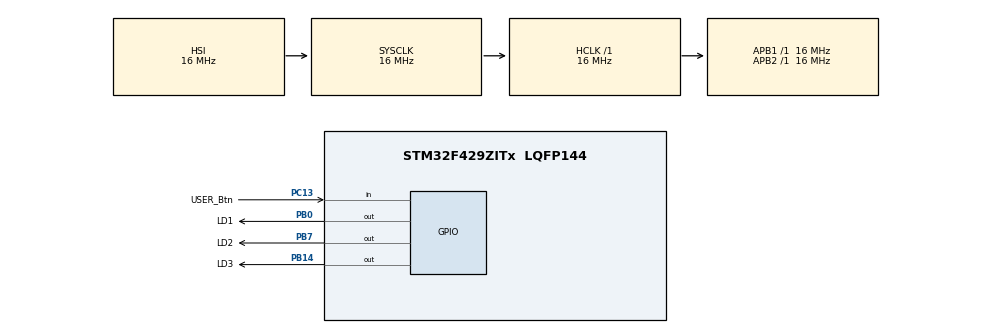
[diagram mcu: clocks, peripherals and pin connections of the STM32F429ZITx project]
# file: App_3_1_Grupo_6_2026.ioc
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Mcu.Family=STM32F4
Mcu.Name=STM32F429ZITx
Mcu.Package=LQFP144
NVIC.PriorityGroup=NVIC_PRIORITYGROUP_4
PB0.GPIO_Label=LD1
PB0.Signal=GPIO_Output
PB14.GPIO_Label=LD3
PB14.Signal=GPIO_Output
PB7.GPIO_Label=LD2
PB7.Signal=GPIO_Output
PC13.GPIO_Label=USER_Btn
PC13.Signal=GPIO_Input
ProjectManager.HeapSize=0x200
ProjectManager.StackSize=0x400
ProjectManager.TargetToolchain=STM32CubeIDE
RCC.AHBFreq_Value=16000000
RCC.APB1Freq_Value=16000000
RCC.APB2Freq_Value=16000000
RCC.CortexFreq_Value=16000000
RCC.HSE_VALUE=25000000
RCC.HSI_VALUE=16000000
RCC.LSE_VALUE=32768
RCC.SYSCLKFreq_VALUE=16000000
RCC.VCOOutputFreq_Value=192000000
board=custom

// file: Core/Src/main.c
/* USER CODE BEGIN Header */
/**
  ******************************************************************************
  * @file           : main.c
  * @brief          : Main program body
  ******************************************************************************
  * @attention
  *
  * Copyright (c) 2026 STMicroelectronics.
  * All rights reserved.
  *
  * This software is licensed under terms that can be found in the LICENSE file
  * in the root directory of this software component.
  * If no LICENSE file comes with this software, it is provided AS-IS.
  *
  ******************************************************************************
  */
/* USER CODE END Header */
#include "main.h"
/*App 1.1: Desarrolle una aplicaci´on que encienda y apague de manera secuencial
los tres leds onboard de la placa de desarrollo. La secuencia debe encender 200 ms y
apagar 200 ms cada led comenzando por el LED1 (Green), continuando con el LED2 (Blue) y
luego el LED3 (Red) para volver a iniciar con el LED1. La aplicaci´on debe ser de car´acter
general, de manera que pueda extenderse a una cantidad mayor de leds con m´ınimas modificaciones,
por este motivo se sugiere que use un vector para el manejo de los Leds.*/
/* USER CODE BEGIN Includes */
#include "API_GPIO.h"
/* USER CODE END Includes */

#define LED1 GPIO_PIN_0    // verde
#define LED2 GPIO_PIN_7    // azul
#define LED3 GPIO_PIN_14   // rojo

void SystemClock_Config(void);
//tatic void MX_GPIO_Init(void);

int main(void)
{

  /* MCU Configuration--------------------------------------------------------*/

  /* Reset of all peripherals, Initializes the Flash interface and the Systick. */
  HAL_Init();

  /* Configure the system clock */
  SystemClock_Config();

  /* Initialize all configured peripherals */
  MX_GPIO_Init();
  /* USER CODE BEGIN 2 */
  /* USER CODE BEGIN 2 */
  led_t leds[] = {LED1, LED2, LED3};   // vector con los leds en el orden de la secuencia
  uint8_t cantLeds = 3;                // cuantos leds hay
  /* USER CODE END 2 */
  /* USER CODE END 2 */

  /* Infinite loop */
  while (1)
  {

    /* USER CODE BEGIN 3 */

	  for (uint8_t i = 0; i < cantLeds; i++)
	  {
		  writeLedOn_GPIO(leds[i]); // acá, leds[i] es el led que toca
		  HAL_Delay(200);
		  writeLedOff_GPIO(leds[i]);
		  HAL_Delay(200);
	  }

  }

  /* USER CODE END 3 */
}

void SystemClock_Config(void)
{
  RCC_OscInitTypeDef RCC_OscInitStruct = {0};
  RCC_ClkInitTypeDef RCC_ClkInitStruct = {0};

  /** Configure the main internal regulator output voltage
  */
  __HAL_RCC_PWR_CLK_ENABLE();
  __HAL_PWR_VOLTAGESCALING_CONFIG(PWR_REGULATOR_VOLTAGE_SCALE3);

  /** Initializes the RCC Oscillators according to the specified parameters
  * in the RCC_OscInitTypeDef structure.
  */
  RCC_OscInitStruct.OscillatorType = RCC_OSCILLATORTYPE_HSI;
  RCC_OscInitStruct.HSIState = RCC_HSI_ON;
  RCC_OscInitStruct.HSICalibrationValue = RCC_HSICALIBRATION_DEFAULT;
  RCC_OscInitStruct.PLL.PLLState = RCC_PLL_NONE;
  if (HAL_RCC_OscConfig(&RCC_OscInitStruct) != HAL_OK)
  {
    Error_Handler();
  }

  /** Initializes the CPU, AHB and APB buses clocks
  */
  RCC_ClkInitStruct.ClockType = RCC_CLOCKTYPE_HCLK|RCC_CLOCKTYPE_SYSCLK
                              |RCC_CLOCKTYPE_PCLK1|RCC_CLOCKTYPE_PCLK2;
  RCC_ClkInitStruct.SYSCLKSource = RCC_SYSCLKSOURCE_HSI;
  RCC_ClkInitStruct.AHBCLKDivider = RCC_SYSCLK_DIV1;
  RCC_ClkInitStruct.APB1CLKDivider = RCC_HCLK_DIV1;
  RCC_ClkInitStruct.APB2CLKDivider = RCC_HCLK_DIV1;

  if (HAL_RCC_ClockConfig(&RCC_ClkInitStruct, FLASH_LATENCY_0) != HAL_OK)
  {
    Error_Handler();
  }
}

void Error_Handler(void)
{
  __disable_irq();
  while (1)
  {
  }
}
